# STM8L051F3 register map
Vendor: STMicroelectronics; Series: STM8L/STM8AL, low density; File version: 1.0
CPU: other r1p0, big endian, no MPU, no FPU, 4 interrupt priority bits
Registers are 8-bit, read-write, reset 0x0 unless marked. A register's access mark holds for its fields unless they carry their own. Offsets are from the block's base; [hi:lo] are bit positions; {n}, {i} and the like mark numbered series.

## SPI1
Base 0x00005200
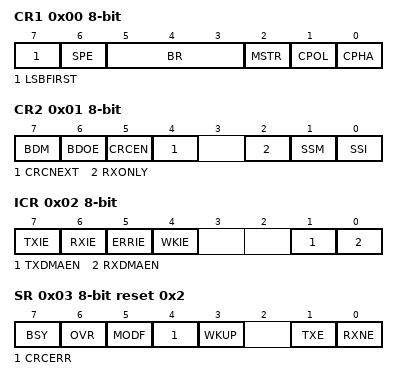
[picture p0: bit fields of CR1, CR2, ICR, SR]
0x00 CR1 — SPI1 control register 1
  [7] LSBFIRST, [6] SPE, [5:3] BR, [2] MSTR, [1] CPOL, [0] CPHA
0x01 CR2 — SPI1 control register 2
  [7] BDM, [6] BDOE, [5] CRCEN, [4] CRCNEXT, [2] RXONLY, [1] SSM, [0] SSI
0x02 ICR — SPI1 interrupt control register
  [7] TXIE, [6] RXIE, [5] ERRIE, [4] WKIE, [1] TXDMAEN, [0] RXDMAEN
0x03 SR reset 0x2 — SPI1 status register
  [7] BSY, [6] OVR, [5] MODF, [4] CRCERR, [3] WKUP, [1] TXE, [0] RXNE
0x04 DR — SPI1 data register
0x05 CRCPR reset 0x7 — SPI1 CRC polynomial register
  [7:0] CRCPOLY
0x06 RXCRCR — SPI1 Rx CRC register
  [7:0] RXCRC
0x07 TXCRCR — SPI1 Tx CRC register
  [6:0] TXCRC

## SWIM
Base 0x00007F80
0x00 CSR — SWIM control status register

## TIM2
Base 0x00005250
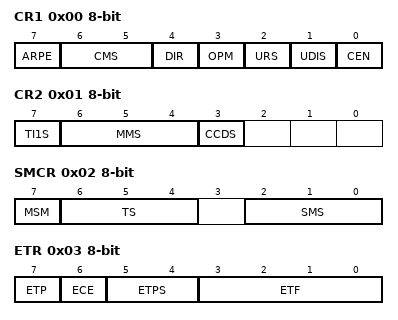
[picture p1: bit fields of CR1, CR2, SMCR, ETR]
0x00 CR1 — TIM2 control register 1
  [7] ARPE, [6:5] CMS, [4] DIR, [3] OPM, [2] URS, [1] UDIS, [0] CEN
0x01 CR2 — TIM2 control register 2
  [7] TI1S, [6:4] MMS, [3] CCDS
0x02 SMCR — TIM2 Slave mode control register
  [7] MSM, [6:4] TS, [2:0] SMS
0x03 ETR — TIM2 external trigger register
  [7] ETP, [6] ECE, [5:4] ETPS, [3:0] ETF
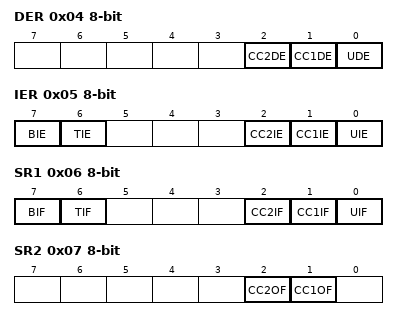
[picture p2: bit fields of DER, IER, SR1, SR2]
0x04 DER — TIM2 DMA1 request enable register
  [2] CC2DE, [1] CC1DE, [0] UDE
0x05 IER — TIM2 interrupt enable register
  [7] BIE, [6] TIE, [2] CC2IE, [1] CC1IE, [0] UIE
0x06 SR1 — TIM2 status register 1
  [7] BIF, [6] TIF, [2] CC2IF, [1] CC1IF, [0] UIF
0x07 SR2 — TIM2 status register 2
  [2] CC2OF, [1] CC1OF
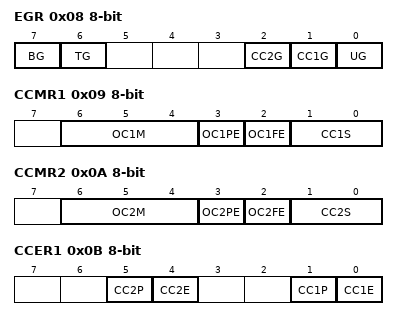
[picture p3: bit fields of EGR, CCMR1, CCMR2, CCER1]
0x08 EGR — TIM2 event generation register
  [7] BG, [6] TG, [2] CC2G, [1] CC1G, [0] UG
0x09 CCMR1 — TIM2 capture/compare mode register 1
  [6:4] OC1M, [3] OC1PE, [2] OC1FE, [1:0] CC1S
0x0A CCMR2 — TIM2 capture/compare mode register 2
  [6:4] OC2M, [3] OC2PE, [2] OC2FE, [1:0] CC2S
0x0B CCER1 — TIM2 capture/compare enable register 1
  [5] CC2P, [4] CC2E, [1] CC1P, [0] CC1E
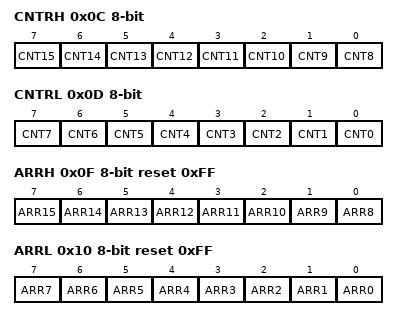
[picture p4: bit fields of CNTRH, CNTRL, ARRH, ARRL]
0x0C CNTRH — TIM2 counter high
  [n-8] CNT{n} (n=8..15)
0x0D CNTRL — TIM2 counter low
  [n] CNT{n} (n=0..7)
0x0E PSCR — TIM2 prescaler register
  [2:0] PSC
0x0F ARRH reset 0xFF — TIM2 auto-reload register high
  [n-8] ARR{n} (n=8..15)
0x10 ARRL reset 0xFF — TIM2 auto-reload register low
  [n] ARR{n} (n=0..7)
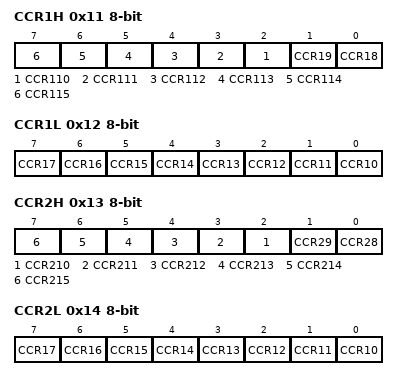
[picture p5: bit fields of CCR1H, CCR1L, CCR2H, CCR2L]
0x11 CCR1H — TIM2 capture/compare register 1 high
  [n-108] CCR{n} (n=110..115), [1] CCR19, [0] CCR18
0x12 CCR1L — TIM2 capture/compare register 1 low
  [n-10] CCR{n} (n=10..17)
0x13 CCR2H — TIM2 capture/compare register 2 high
  [n-208] CCR{n} (n=210..215), [1] CCR29, [0] CCR28
0x14 CCR2L — TIM2 capture/compare register 2 low
  [n-10] CCR{n} (n=10..17)
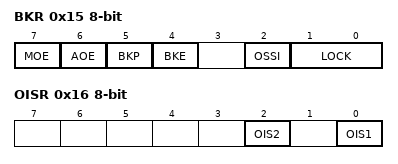
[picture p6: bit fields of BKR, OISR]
0x15 BKR — TIM2 break register
  [7] MOE, [6] AOE, [5] BKP, [4] BKE, [2] OSSI, [1:0] LOCK
0x16 OISR — TIM2 output idle state register
  [2] OIS2, [0] OIS1

## TIM3
Base 0x00005280
Registers as TIM2 (with TIM2 read as TIM3); these are added or differ:
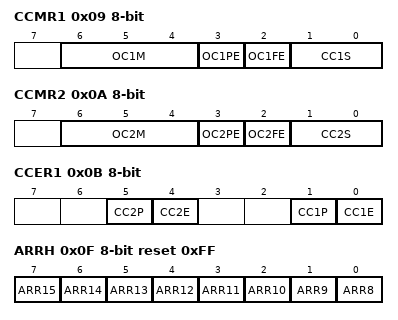
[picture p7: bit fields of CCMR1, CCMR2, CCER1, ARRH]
0x09 CCMR1 — TIM3 Capture/Compare mode register 1
  [6:4] OC1M, [3] OC1PE, [2] OC1FE, [1:0] CC1S
0x0A CCMR2 — TIM3 Capture/Compare mode register 2
  [6:4] OC2M, [3] OC2PE, [2] OC2FE, [1:0] CC2S
0x0B CCER1 — TIM3 Capture/Compare enable register 1
  [5] CC2P, [4] CC2E, [1] CC1P, [0] CC1E
0x0F ARRH reset 0xFF — TIM3 Auto-reload register high
  [n-8] ARR{n} (n=8..15)
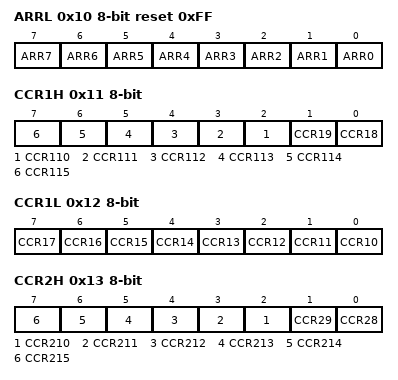
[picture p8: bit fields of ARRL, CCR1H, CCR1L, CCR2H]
0x10 ARRL reset 0xFF — TIM3 Auto-reload register low
  [n] ARR{n} (n=0..7)
0x11 CCR1H — TIM3 Capture/Compare register 1 high
  [n-108] CCR{n} (n=110..115), [1] CCR19, [0] CCR18
0x12 CCR1L — TIM3 Capture/Compare register 1 low
  [n-10] CCR{n} (n=10..17)
0x13 CCR2H — TIM3 Capture/Compare register 2 high
  [n-208] CCR{n} (n=210..215), [1] CCR29, [0] CCR28
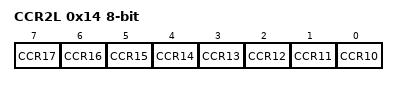
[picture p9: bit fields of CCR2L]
0x14 CCR2L — TIM3 Capture/Compare register 2 low
  [n-10] CCR{n} (n=10..17)

## TIM4
Base 0x000052E0
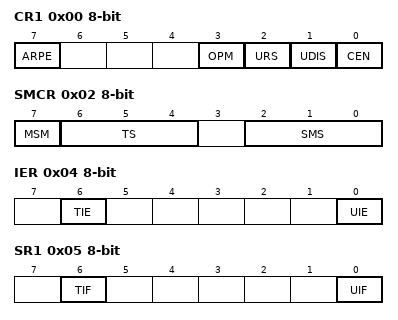
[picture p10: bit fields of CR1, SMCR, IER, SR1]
0x00 CR1 — TIM4 control register 1
  [7] ARPE, [3] OPM, [2] URS, [1] UDIS, [0] CEN
0x01 CR2 — TIM4 control register 2
  [6:4] MMS
0x02 SMCR — TIM4 Slave mode control register
  [7] MSM, [6:4] TS, [2:0] SMS
0x03 DER — TIM4 DMA1 request enable register
  [0] UDE
0x04 IER — TIM4 Interrupt enable register
  [6] TIE, [0] UIE
0x05 SR1 — TIM4 status register 1
  [6] TIF, [0] UIF
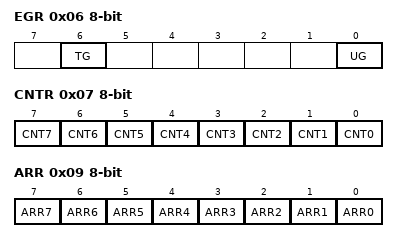
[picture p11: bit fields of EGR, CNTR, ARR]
0x06 EGR — TIM4 Event generation register
  [6] TG, [0] UG
0x07 CNTR — TIM4 counter
  [n] CNT{n} (n=0..7)
0x08 PSCR — TIM4 prescaler register
  [3:0] PSC
0x09 ARR — TIM4 Auto-reload register
  [n] ARR{n} (n=0..7)

## USART1
Base 0x00005230
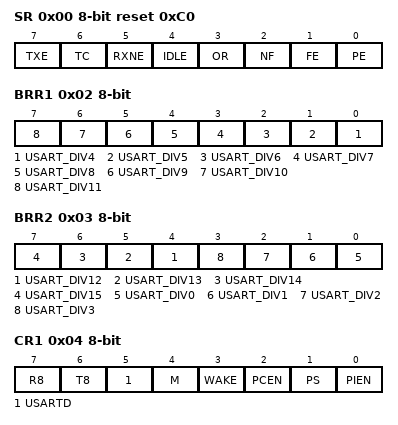
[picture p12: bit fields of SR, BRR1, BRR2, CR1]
0x00 SR reset 0xC0 — USART1 status register
  [7] TXE, [6] TC, [5] RXNE, [4] IDLE, [3] OR, [2] NF, [1] FE, [0] PE
0x01 DR — USART1 data register
0x02 BRR1 — USART1 baud rate register 1
  [n-4] USART_DIV{n} (n=4..11)
0x03 BRR2 — USART1 baud rate register 2
  [n-8] USART_DIV{n} (n=12..15), [n] USART_DIV{n} (n=0..3)
0x04 CR1 — USART1 control register 1
  [7] R8, [6] T8, [5] USARTD, [4] M, [3] WAKE, [2] PCEN, [1] PS, [0] PIEN
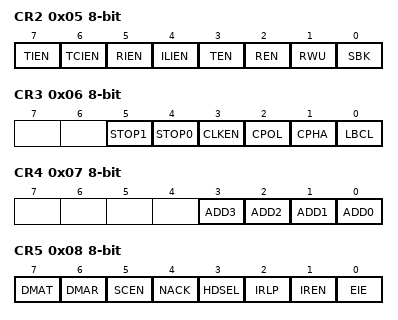
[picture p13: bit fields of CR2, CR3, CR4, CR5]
0x05 CR2 — USART1 control register 2
  [7] TIEN, [6] TCIEN, [5] RIEN, [4] ILIEN, [3] TEN, [2] REN, [1] RWU, [0] SBK
0x06 CR3 — USART1 control register 3
  [5] STOP1, [4] STOP0, [3] CLKEN, [2] CPOL, [1] CPHA, [0] LBCL
0x07 CR4 — USART1 control register 4
  [n] ADD{n} (n=0..3)
0x08 CR5 — USART1 control register 5
  [7] DMAT, [6] DMAR, [5] SCEN, [4] NACK, [3] HDSEL, [2] IRLP, [1] IREN, [0] EIE
0x09 GTR — USART1 guard time register
  [7:0] GT
0x0A PSCR — USART1 prescaler register
  [7:0] PSC

## WFE
Base 0x000050A6
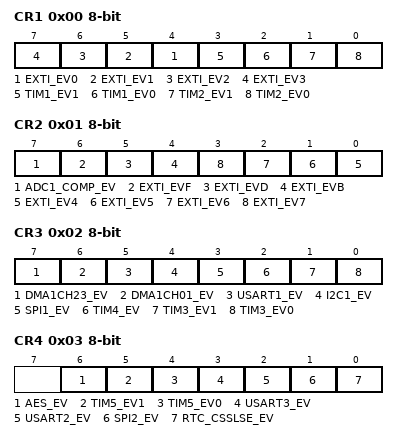
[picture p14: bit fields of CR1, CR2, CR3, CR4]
0x00 CR1 — WFE control register 1
  [n+4] EXTI_EV{n} (n=0..3), [3] TIM1_EV1, [2] TIM1_EV0, [1] TIM2_EV1, [0] TIM2_EV0
0x01 CR2 — WFE control register 2
  [7] ADC1_COMP_EV, [6] EXTI_EVF, [5] EXTI_EVD, [4] EXTI_EVB, [n-4] EXTI_EV{n} (n=4..7)
0x02 CR3 — WFE control register 3
  [7] DMA1CH23_EV, [6] DMA1CH01_EV, [5] USART1_EV, [4] I2C1_EV, [3] SPI1_EV, [2] TIM4_EV, [1] TIM3_EV1, [0] TIM3_EV0
0x03 CR4 — WFE control register 4
  [6] AES_EV, [5] TIM5_EV1, [4] TIM5_EV0, [3] USART3_EV, [2] USART2_EV, [1] SPI2_EV, [0] RTC_CSSLSE_EV

## WWDG
Base 0x000050D3
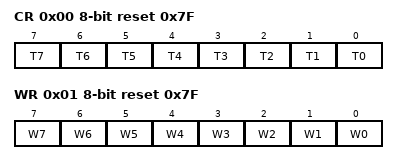
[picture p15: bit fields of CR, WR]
0x00 CR reset 0x7F — WWDG control register
  [n] T{n} (n=0..7)
0x01 WR reset 0x7F — WWDR window register
  [n] W{n} (n=0..7)
